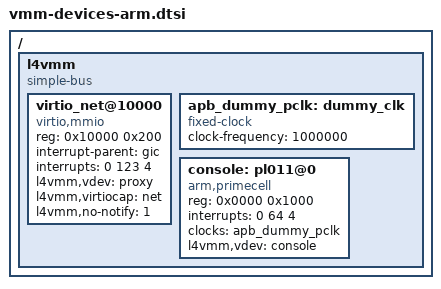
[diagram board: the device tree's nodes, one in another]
/**
 * Basic set of VMM virtual devices for ARM guests.
 *
 *  * console device
 *  * network virtio proxy device
 */

/ {
    l4vmm {
        #address-cells = <1>;
        #size-cells = <1>;
        compatible = "simple-bus";
        ranges = <0x0 0x30000000 0x21000>;

        virtio_net@10000 {
            compatible = "virtio,mmio";
            reg = <0x10000 0x200>;
            interrupt-parent = <&gic>;
            interrupts = <0 123 4>;
            l4vmm,vdev = "proxy";
            l4vmm,virtiocap = "net";
            l4vmm,no-notify = <1>;
        };

        apb_dummy_pclk: dummy_clk {
                compatible = "fixed-clock";
                #clock-cells = <0>;
                clock-frequency = <1000000>;
        };

        console: pl011@0 {
                compatible = "arm,primecell", "arm,pl011";
                reg = <0x0000 0x1000>;
                interrupts = <0 64 4>;
                clocks = <&apb_dummy_pclk>;
                clock-names = "apb_pclk";
                l4vmm,vdev = "console";
        };
    };
};
